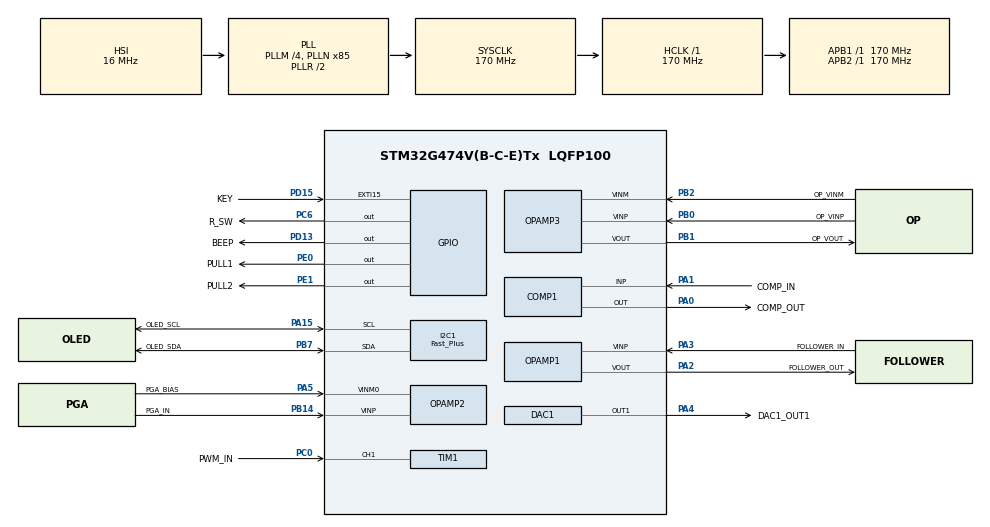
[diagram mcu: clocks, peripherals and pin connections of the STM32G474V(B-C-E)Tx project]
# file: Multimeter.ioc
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ADC2.Channel-2\#ChannelRegularConversion=ADC_CHANNEL_VOPAMP2
ADC2.ContinuousConvMode=ENABLE
ADC2.DMAContinuousRequests=ENABLE
ADC2.NbrOfConversionFlag=1
ADC2.OffsetNumber-2\#ChannelRegularConversion=ADC_OFFSET_NONE
ADC2.OversamplingMode=ENABLE
ADC2.Rank-2\#ChannelRegularConversion=1
ADC2.Ratio=ADC_OVERSAMPLING_RATIO_256
ADC2.RightBitShift=ADC_RIGHTBITSHIFT_4
ADC2.SamplingTime-2\#ChannelRegularConversion=ADC_SAMPLETIME_640CYCLES_5
COMP1.Hysteresis=COMP_HYSTERESIS_30MV
COMP7.Hysteresis=COMP_HYSTERESIS_MEDIUM
COMP7.TriggerMode=COMP_TRIGGERMODE_IT_RISING
DAC1.DAC_OutputBuffer-DAC_OUT1=DAC_OUTPUTBUFFER_DISABLE
Dma.ADC2.0.Direction=DMA_PERIPH_TO_MEMORY
Dma.ADC2.0.EventEnable=DISABLE
Dma.ADC2.0.Instance=DMA1_Channel1
Dma.ADC2.0.MemDataAlignment=DMA_MDATAALIGN_HALFWORD
Dma.ADC2.0.MemInc=DMA_MINC_ENABLE
Dma.ADC2.0.Mode=DMA_CIRCULAR
Dma.ADC2.0.PeriphDataAlignment=DMA_PDATAALIGN_HALFWORD
Dma.ADC2.0.PeriphInc=DMA_PINC_DISABLE
Dma.ADC2.0.Polarity=HAL_DMAMUX_REQ_GEN_RISING
Dma.ADC2.0.Priority=DMA_PRIORITY_MEDIUM
Dma.ADC2.0.RequestNumber=1
Dma.ADC2.0.SignalID=NONE
Dma.ADC2.0.SyncEnable=DISABLE
Dma.ADC2.0.SyncPolarity=HAL_DMAMUX_SYNC_NO_EVENT
Dma.ADC2.0.SyncRequestNumber=1
Dma.ADC2.0.SyncSignalID=NONE
Dma.Request0=ADC2
I2C1.I2C_Speed_Mode=I2C_Fast_Plus
I2C1.Timing=0x4052060F
Mcu.Family=STM32G4
Mcu.Name=STM32G474V(B-C-E)Tx
Mcu.Package=LQFP100
NVIC.ADC1_2_IRQn=true\:0\:0\:false\:false\:true\:true\:true\:true
NVIC.COMP7_IRQn=true\:0\:0\:false\:false\:true\:false\:true\:true
NVIC.DMA1_Channel1_IRQn=true\:0\:0\:false\:false\:true\:false\:true\:true
NVIC.EXTI15_10_IRQn=true\:0\:0\:false\:false\:true\:true\:true\:true
NVIC.PriorityGroup=NVIC_PRIORITYGROUP_4
NVIC.TIM1_CC_IRQn=true\:0\:0\:false\:false\:true\:true\:true\:true
NVIC.TIM2_IRQn=true\:0\:0\:false\:false\:true\:true\:true\:true
OPAMP1.PowerMode=OPAMP_POWERMODE_HIGHSPEED
OPAMP2.PowerMode=OPAMP_POWERMODE_HIGHSPEED
OPAMP3.PowerMode=OPAMP_POWERMODE_HIGHSPEED
PA0.GPIO_Label=COMP_OUT
PA0.GPIO_Speed=GPIO_SPEED_FREQ_VERY_HIGH
PA0.Mode=ExternalOutput
PA0.Signal=COMP1_OUT
PA1.GPIO_Label=COMP_IN
PA1.Mode=INP
PA1.Signal=COMP1_INP
PA13.Mode=Serial_Wire
PA13.Signal=SYS_JTMS-SWDIO
PA14.Mode=Serial_Wire
PA14.Signal=SYS_JTCK-SWCLK
PA15.GPIO_Label=OLED_SCL
PA15.Mode=I2C
PA15.Signal=I2C1_SCL
PA2.GPIO_Label=FOLLOWER_OUT
PA2.Mode=Follower
PA2.Signal=OPAMP1_VOUT
PA3.GPIO_Label=FOLLOWER_IN
PA3.Mode=Follower
PA3.Signal=OPAMP1_VINP
PA4.GPIO_Label=DAC1_OUT1
PA4.Signal=COMP_DAC11_group
PA5.GPIO_Label=PGA_BIAS
PA5.Mode=PGA Internally connected_IO0_BIAS
PA5.Signal=OPAMP2_VINM0
PB0.GPIO_Label=OP_VINP
PB0.Mode=Standalone
PB0.Signal=OPAMP3_VINP
PB1.GPIO_Label=OP_VOUT
PB1.Mode=Standalone
PB1.Signal=OPAMP3_VOUT
PB14.GPIO_Label=PGA_IN
PB14.Signal=SharedAnalog_PB14
PB2.GPIO_Label=OP_VINM
PB2.Mode=Standalone
PB2.Signal=OPAMP3_VINM
PB7.GPIO_Label=OLED_SDA
PB7.Mode=I2C
PB7.Signal=I2C1_SDA
PC0.GPIO_Label=PWM_IN
PC0.Signal=S_TIM1_CH1
PC6.GPIO_Label=R_SW
PC6.Signal=GPIO_Output
PD13.GPIO_Label=BEEP
PD13.Signal=GPIO_Output
PD15.GPIO_Label=KEY
PD15.GPIO_ModeDefaultEXTI=GPIO_MODE_IT_RISING_FALLING
PD15.GPIO_PuPd=GPIO_PULLUP
PD15.Signal=GPXTI15
PE0.GPIO_Label=PULL1
PE0.GPIO_PuPd=GPIO_NOPULL
PE0.Signal=GPIO_Output
PE1.GPIO_Label=PULL2
PE1.GPIO_PuPd=GPIO_NOPULL
PE1.Signal=GPIO_Output
PF0-OSC_IN.Mode=HSE-External-Oscillator
PF0-OSC_IN.Signal=RCC_OSC_IN
PF1-OSC_OUT.Mode=HSE-External-Oscillator
PF1-OSC_OUT.Signal=RCC_OSC_OUT
ProjectManager.HeapSize=0x200
ProjectManager.StackSize=0x400
ProjectManager.TargetToolchain=CMake
RCC.ADC12Freq_Value=170000000
RCC.ADC345Freq_Value=170000000
RCC.AHBFreq_Value=170000000
RCC.APB1Freq_Value=170000000
RCC.APB1TimFreq_Value=170000000
RCC.APB2Freq_Value=170000000
RCC.APB2TimFreq_Value=170000000
RCC.CortexFreq_Value=170000000
RCC.EXTERNAL_CLOCK_VALUE=12288000
RCC.HCLKFreq_Value=170000000
RCC.HSE_VALUE=8000000
RCC.HSI48_VALUE=48000000
RCC.HSI_VALUE=16000000
RCC.LSE_VALUE=32768
RCC.PLLM=RCC_PLLM_DIV4
RCC.PLLN=85
RCC.SYSCLKFreq_VALUE=170000000
RCC.SYSCLKSource=RCC_SYSCLKSOURCE_PLLCLK
RCC.USBFreq_Value=170000000
RCC.VCOOutputFreq_Value=340000000
SH.COMP_DAC11_group.0=DAC1_OUT1,DAC_OUT1
SH.S_TIM1_CH1.0=TIM1_CH1,PWM_Input_1
SH.SharedAnalog_PB14.0=OPAMP2_VINP,PGA Internally connected_IO0_BIAS
SH.SharedAnalog_PB14.1=COMP7_INP,INP
STMicroelectronics.X-CUBE-ALGOBUILD.1.4.0.LibraryCcDSPOoLibraryJjDSPOoLibrary=true
VP_ADC2_OPAMP_INTERNAL2.Mode=IN-OPAMP2
VP_COMP1_VS_DAC3OUT1.Mode=INM_DAC3OUT1
VP_COMP7_VS_DAC2OUT1.Mode=INM_DAC2OUT1
VP_DAC2_VS_DACI1.Mode=DAC_OUT1_Int
VP_DAC3_VS_DACI1.Mode=DAC_OUT1_Int
VP_STMicroelectronics.X-CUBE-ALGOBUILD_VS_DSPOoLibraryJjLibrary_1.4.0_1.4.0.Mode=DSPOoLibraryJjLibrary
VP_SYS_VS_DBSignals.Mode=DisableDeadBatterySignals
VP_SYS_V_VREFBUF.Mode=ExternalMode
VP_TIM1_VS_ClockSourceINT.Mode=Internal
VP_TIM2_VS_ClockSourceINT.Mode=Internal
board=custom

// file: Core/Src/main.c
/* USER CODE BEGIN Header */
/**
  ******************************************************************************
  * @file           : main.c
  * @brief          : Main program body
  ******************************************************************************
  * @attention
  *
  * Copyright (c) 2026 STMicroelectronics.
  * All rights reserved.
  *
  * This software is licensed under terms that can be found in the LICENSE file
  * in the root directory of this software component.
  * If no LICENSE file comes with this software, it is provided AS-IS.
  *
  ******************************************************************************
  */
/* USER CODE END Header */
#include "main.h"
#include "adc.h"
#include "comp.h"
#include "dac.h"
#include "dma.h"
#include "i2c.h"
#include "opamp.h"
#include "tim.h"
#include "gpio.h"

/* USER CODE BEGIN Includes */
#include "app.h"
#include "SEGGER_RTT.h"
/* USER CODE END Includes */

void SystemClock_Config(void);

int main(void)
{

  /* MCU Configuration--------------------------------------------------------*/

  /* Reset of all peripherals, Initializes the Flash interface and the Systick. */
  HAL_Init();

  /* USER CODE BEGIN Init */
  SEGGER_RTT_Init();
  /* USER CODE END Init */

  /* Configure the system clock */
  SystemClock_Config();

  /* Initialize all configured peripherals */
  MX_GPIO_Init();
  MX_DMA_Init();
  MX_OPAMP1_Init();
  MX_OPAMP2_Init();
  MX_COMP1_Init();
  MX_OPAMP3_Init();
  MX_TIM1_Init();
  MX_DAC1_Init();
  MX_I2C1_Init();
  MX_ADC2_Init();
  MX_DAC3_Init();
  MX_TIM2_Init();
  MX_COMP7_Init();
  MX_DAC2_Init();
  /* USER CODE BEGIN 2 */
  APP_Init();

  /* USER CODE END 2 */

  /* Infinite loop */
  /* USER CODE BEGIN WHILE */
  while (1)
  {
    APP_Proc();
    HAL_Delay(20);

    /* USER CODE END WHILE */

  }
}

void SystemClock_Config(void)
{
  RCC_OscInitTypeDef RCC_OscInitStruct = {0};
  RCC_ClkInitTypeDef RCC_ClkInitStruct = {0};

  /** Configure the main internal regulator output voltage
  */
  HAL_PWREx_ControlVoltageScaling(PWR_REGULATOR_VOLTAGE_SCALE1_BOOST);

  /** Initializes the RCC Oscillators according to the specified parameters
  * in the RCC_OscInitTypeDef structure.
  */
  RCC_OscInitStruct.OscillatorType = RCC_OSCILLATORTYPE_HSI;
  RCC_OscInitStruct.HSIState = RCC_HSI_ON;
  RCC_OscInitStruct.HSICalibrationValue = RCC_HSICALIBRATION_DEFAULT;
  RCC_OscInitStruct.PLL.PLLState = RCC_PLL_ON;
  RCC_OscInitStruct.PLL.PLLSource = RCC_PLLSOURCE_HSI;
  RCC_OscInitStruct.PLL.PLLM = RCC_PLLM_DIV4;
  RCC_OscInitStruct.PLL.PLLN = 85;
  RCC_OscInitStruct.PLL.PLLP = RCC_PLLP_DIV2;
  RCC_OscInitStruct.PLL.PLLQ = RCC_PLLQ_DIV2;
  RCC_OscInitStruct.PLL.PLLR = RCC_PLLR_DIV2;
  if (HAL_RCC_OscConfig(&RCC_OscInitStruct) != HAL_OK)
  {
    Error_Handler();
  }

  /** Initializes the CPU, AHB and APB buses clocks
  */
  RCC_ClkInitStruct.ClockType = RCC_CLOCKTYPE_HCLK|RCC_CLOCKTYPE_SYSCLK
                              |RCC_CLOCKTYPE_PCLK1|RCC_CLOCKTYPE_PCLK2;
  RCC_ClkInitStruct.SYSCLKSource = RCC_SYSCLKSOURCE_PLLCLK;
  RCC_ClkInitStruct.AHBCLKDivider = RCC_SYSCLK_DIV1;
  RCC_ClkInitStruct.APB1CLKDivider = RCC_HCLK_DIV1;
  RCC_ClkInitStruct.APB2CLKDivider = RCC_HCLK_DIV1;

  if (HAL_RCC_ClockConfig(&RCC_ClkInitStruct, FLASH_LATENCY_4) != HAL_OK)
  {
    Error_Handler();
  }
}

void Error_Handler(void)
{
  __disable_irq();
  while (1)
  {
  }
}
